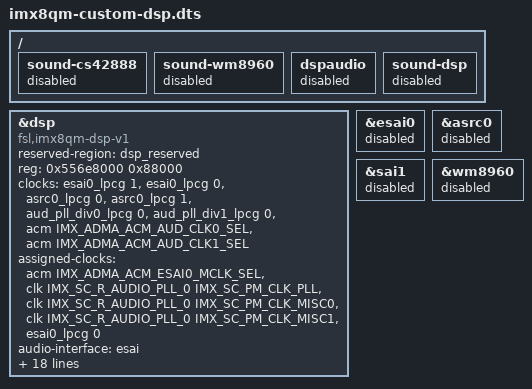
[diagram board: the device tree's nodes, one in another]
// SPDX-License-Identifier: GPL-2.0+
// Copyright NXP 2018

#include "imx8qm-custom-rpmsg.dts"

/ {
	sound-cs42888 {
		status = "disabled";
	};

	sound-wm8960 {
		status = "disabled";
	};

	dspaudio: dspaudio {
		status = "disabled";
	};

	sound-dsp {
		status = "disabled";
	};
};

&dsp {
	compatible = "fsl,imx8qm-dsp-v1";
	reserved-region = <&dsp_reserved>;
	reg = <0x556e8000 0x88000>;
	clocks = <&esai0_lpcg 1>,
		<&esai0_lpcg 0>,
		<&asrc0_lpcg 0>,
		<&asrc0_lpcg 1>,
		<&aud_pll_div0_lpcg 0>,
		<&aud_pll_div1_lpcg 0>,
		<&acm IMX_ADMA_ACM_AUD_CLK0_SEL>,
		<&acm IMX_ADMA_ACM_AUD_CLK1_SEL>;
	clock-names = "esai_ipg", "esai_mclk", "asrc_ipg", "asrc_mem",
			"asrck_0", "asrck_1", "asrck_2", "asrck_3";
	assigned-clocks = <&acm IMX_ADMA_ACM_ESAI0_MCLK_SEL>,
			<&clk IMX_SC_R_AUDIO_PLL_0 IMX_SC_PM_CLK_PLL>,
			<&clk IMX_SC_R_AUDIO_PLL_0 IMX_SC_PM_CLK_MISC0>,
			<&clk IMX_SC_R_AUDIO_PLL_0 IMX_SC_PM_CLK_MISC1>,
			<&esai0_lpcg 0>;
	audio-interface = "esai";
	assigned-clock-parents = <&aud_pll_div0_lpcg 0>;
	assigned-clock-rates = <0>, <786432000>, <49152000>, <12288000>, <49152000>;
	fsl,dsp-firmware = "imx/dsp/hifi4.bin";
	power-domains = <&pd IMX_SC_R_MU_13A>,
			<&pd IMX_SC_R_MU_13B>,
			<&pd IMX_SC_R_IRQSTR_DSP>,
			<&pd IMX_SC_R_DSP>,
			<&pd IMX_SC_R_DSP_RAM>,
			<&pd IMX_SC_R_ESAI_0>,
			<&pd IMX_SC_R_DMA_2_CH6>,
			<&pd IMX_SC_R_DMA_2_CH7>,
			<&pd IMX_SC_R_AUDIO_CLK_0>,
			<&pd IMX_SC_R_AUDIO_CLK_1>,
			<&pd IMX_SC_R_AUDIO_PLL_0>,
			<&pd IMX_SC_R_AUDIO_PLL_1>,
			<&pd IMX_SC_R_ASRC_0>,
			<&pd IMX_SC_R_DMA_2_CH0>,
			<&pd IMX_SC_R_DMA_2_CH1>,
			<&pd IMX_SC_R_DMA_2_CH2>,
			<&pd IMX_SC_R_DMA_2_CH3>,
			<&pd IMX_SC_R_DMA_2_CH4>,
			<&pd IMX_SC_R_DMA_2_CH5>;
	status = "okay";
};

&esai0 {
	status = "disabled";
};

&asrc0 {
	status = "disabled";
};

&sai1 {
	status = "disabled";
};

&wm8960 {
	status = "disabled";
};
